# STM32WB15CCU6 register map
File version: 1.0
Registers are 32-bit, access not given, reset 0x0 unless marked. A register's access mark holds for its fields unless they carry their own. Offsets are from the block's base; [hi:lo] are bit positions; {n}, {i} and the like mark numbered series; 'fields as' and 'values as' point back to an identical list.

## TAMP
Base 0x40002800
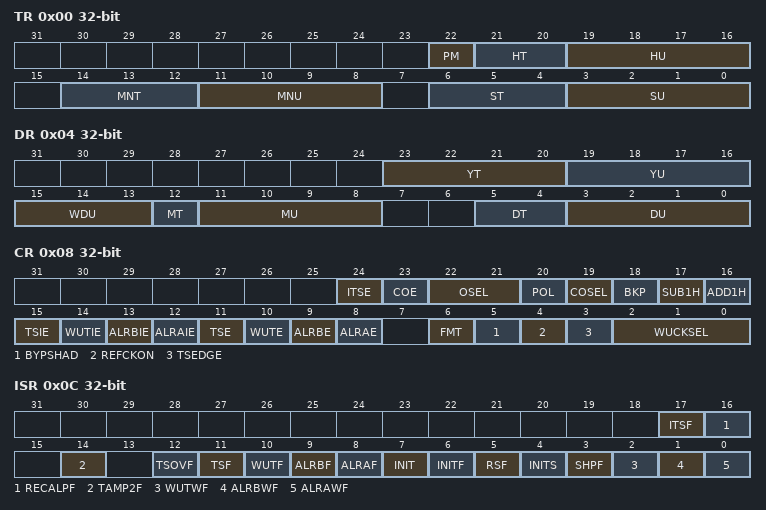
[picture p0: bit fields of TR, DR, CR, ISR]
0x00 TR
  [22] PM, [21:20] HT, [19:16] HU, [14:12] MNT, [11:8] MNU, [6:4] ST, [3:0] SU
0x04 DR
  [23:20] YT, [19:16] YU, [15:13] WDU, [12] MT, [11:8] MU, [5:4] DT, [3:0] DU
0x08 CR
  [24] ITSE, [23] COE, [22:21] OSEL, [20] POL, [19] COSEL, [18] BKP, [17] SUB1H, [16] ADD1H, [15] TSIE, [14] WUTIE, [13] ALRBIE, [12] ALRAIE, [11] TSE, [10] WUTE, [9] ALRBE, [8] ALRAE, [6] FMT, [5] BYPSHAD, [4] REFCKON, [3] TSEDGE, [2:0] WUCKSEL
0x0C ISR
  [17] ITSF, [16] RECALPF, [14] TAMP2F, [12] TSOVF, [11] TSF, [10] WUTF, [9] ALRBF, [8] ALRAF, [7] INIT, [6] INITF, [5] RSF, [4] INITS, [3] SHPF, [2] WUTWF, [1] ALRBWF, [0] ALRAWF
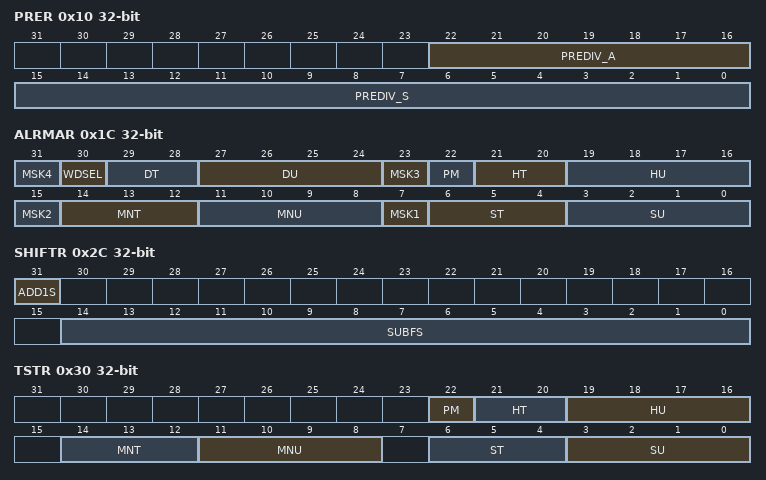
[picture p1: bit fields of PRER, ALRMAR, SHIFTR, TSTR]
0x10 PRER
  [22:16] PREDIV_A, [15:0] PREDIV_S
0x14 WUTR
  [15:0] WUT
0x1C ALRMAR
  [8n-1] MSK{n} (n=1..4), [30] WDSEL, [29:28] DT, [27:24] DU, [22] PM, [21:20] HT, [19:16] HU, [14:12] MNT, [11:8] MNU, [6:4] ST, [3:0] SU
0x20 ALRMBR
  [31] MSK4, [30] WDSEL, [29:28] DT, [27:24] DU, [23] MSK3, [22] PM, [21:20] HT, [19:16] HU, [14:12] MNT, [11:8] MNU, [15:7] MSK2, [6:4] ST, [3:0] SU
0x24 WPR
  [7:0] KEY
0x28 SSR
  [15:0] SS
0x2C SHIFTR
  [31] ADD1S, [14:0] SUBFS
0x30 TSTR
  fields as TR
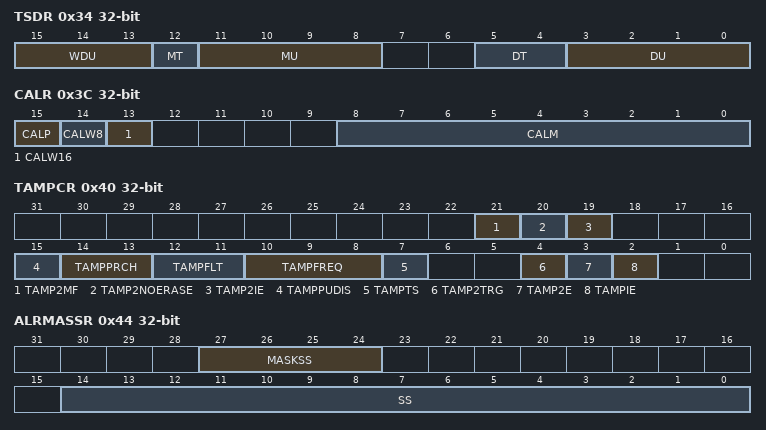
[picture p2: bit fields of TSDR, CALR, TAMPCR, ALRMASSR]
0x34 TSDR
  [15:13] WDU, [12] MT, [11:8] MU, [5:4] DT, [3:0] DU
0x38 TSSSR
  [15:0] SS
0x3C CALR
  [15] CALP, [14] CALW8, [13] CALW16, [8:0] CALM
0x40 TAMPCR
  [21] TAMP2MF, [20] TAMP2NOERASE, [19] TAMP2IE, [15] TAMPPUDIS, [14:13] TAMPPRCH, [12:11] TAMPFLT, [10:8] TAMPFREQ, [7] TAMPTS, [4] TAMP2TRG, [3] TAMP2E, [2] TAMPIE
0x44 ALRMASSR
  [27:24] MASKSS, [14:0] SS
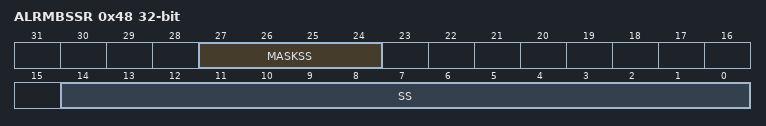
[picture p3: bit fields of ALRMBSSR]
0x48 ALRMBSSR
  [27:24] MASKSS, [14:0] SS
0x4C OR
  [1] RTC_OUT_RMP
{0x50+4i} BKP{i}R (i=0..19)
  [31:0] BKP

## RTC
Base 0x40002800
Registers as TAMP, without TAMPCR; these are added or differ:
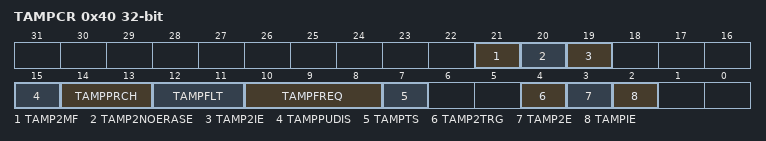
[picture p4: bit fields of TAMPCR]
0x40 TAMPCR
  [21] TAMP2MF, [20] TAMP2NOERASE, [19] TAMP2IE, [15] TAMPPUDIS, [14:13] TAMPPRCH, [12:11] TAMPFLT, [10:8] TAMPFREQ, [7] TAMPTS, [4] TAMP2TRG, [3] TAMP2E, [2] TAMPIE
0x4C OR
  [1] RTC_OUT_RMP

## WWDG
Base 0x40002C00
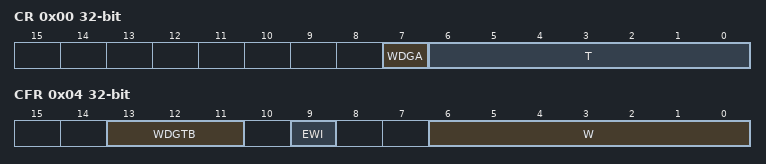
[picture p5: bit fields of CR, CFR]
0x00 CR
  [7] WDGA, [6:0] T
0x04 CFR
  [13:11] WDGTB, [9] EWI, [6:0] W
0x08 SR
  [0] EWIF

## IWDG
Base 0x40003000
0x00 KR
  [15:0] KEY
0x04 PR
  [2:0] PR
0x08 RLR
  [11:0] RL
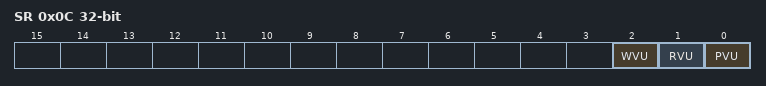
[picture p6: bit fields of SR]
0x0C SR
  [2] WVU, [1] RVU, [0] PVU
0x10 WINR
  [11:0] WIN

## I2C1
Base 0x40005400
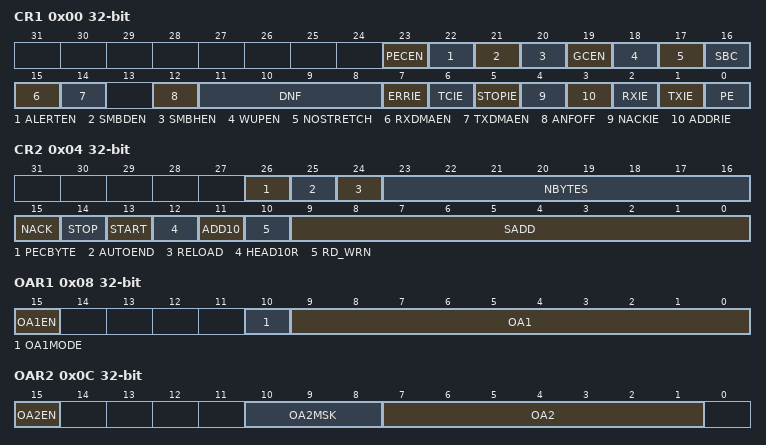
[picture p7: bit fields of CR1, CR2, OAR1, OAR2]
0x00 CR1
  [23] PECEN, [22] ALERTEN, [21] SMBDEN, [20] SMBHEN, [19] GCEN, [18] WUPEN, [17] NOSTRETCH, [16] SBC, [15] RXDMAEN, [14] TXDMAEN, [12] ANFOFF, [11:8] DNF, [7] ERRIE, [6] TCIE, [5] STOPIE, [4] NACKIE, [3] ADDRIE, [2] RXIE, [1] TXIE, [0] PE
0x04 CR2
  [26] PECBYTE, [25] AUTOEND, [24] RELOAD, [23:16] NBYTES, [15] NACK, [14] STOP, [13] START, [12] HEAD10R, [11] ADD10, [10] RD_WRN, [9:0] SADD
0x08 OAR1
  [15] OA1EN, [10] OA1MODE, [9:0] OA1
0x0C OAR2
  [15] OA2EN, [10:8] OA2MSK, [7:1] OA2
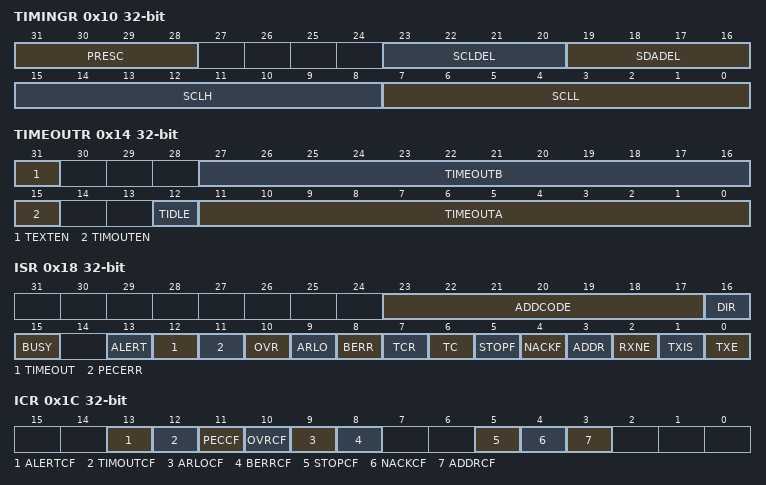
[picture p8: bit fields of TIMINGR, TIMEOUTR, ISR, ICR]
0x10 TIMINGR
  [31:28] PRESC, [23:20] SCLDEL, [19:16] SDADEL, [15:8] SCLH, [7:0] SCLL
0x14 TIMEOUTR
  [31] TEXTEN, [27:16] TIMEOUTB, [15] TIMOUTEN, [12] TIDLE, [11:0] TIMEOUTA
0x18 ISR
  [23:17] ADDCODE, [16] DIR, [15] BUSY, [13] ALERT, [12] TIMEOUT, [11] PECERR, [10] OVR, [9] ARLO, [8] BERR, [7] TCR, [6] TC, [5] STOPF, [4] NACKF, [3] ADDR, [2] RXNE, [1] TXIS, [0] TXE
0x1C ICR
  [13] ALERTCF, [12] TIMOUTCF, [11] PECCF, [10] OVRCF, [9] ARLOCF, [8] BERRCF, [5] STOPCF, [4] NACKCF, [3] ADDRCF
0x20 PECR
  [7:0] PEC
0x24 RXDR
  [7:0] RXDATA
0x28 TXDR
  [7:0] TXDATA

## LPTIM1
Base 0x40007C00
Same registers: LPTIM2 0x40009400
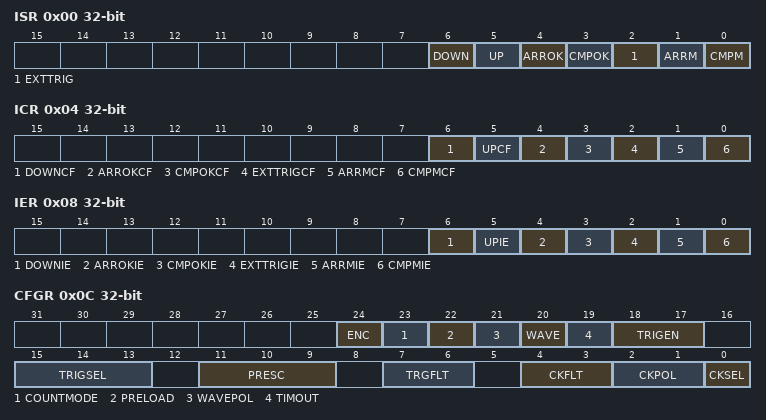
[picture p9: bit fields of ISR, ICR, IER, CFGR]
0x00 ISR
  [6] DOWN, [5] UP, [4] ARROK, [3] CMPOK, [2] EXTTRIG, [1] ARRM, [0] CMPM
0x04 ICR
  [6] DOWNCF, [5] UPCF, [4] ARROKCF, [3] CMPOKCF, [2] EXTTRIGCF, [1] ARRMCF, [0] CMPMCF
0x08 IER
  [6] DOWNIE, [5] UPIE, [4] ARROKIE, [3] CMPOKIE, [2] EXTTRIGIE, [1] ARRMIE, [0] CMPMIE
0x0C CFGR
  [24] ENC, [23] COUNTMODE, [22] PRELOAD, [21] WAVEPOL, [20] WAVE, [19] TIMOUT, [18:17] TRIGEN, [15:13] TRIGSEL, [11:9] PRESC, [7:6] TRGFLT, [4:3] CKFLT, [2:1] CKPOL, [0] CKSEL
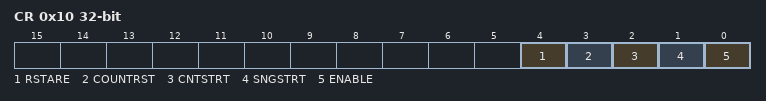
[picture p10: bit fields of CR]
0x10 CR
  [4] RSTARE, [3] COUNTRST, [2] CNTSTRT, [1] SNGSTRT, [0] ENABLE
0x14 CMP
  [15:0] CMP
0x18 ARR
  [15:0] ARR
0x1C CNT
  [15:0] CNT
0x20 OR
  [0] OR_0
